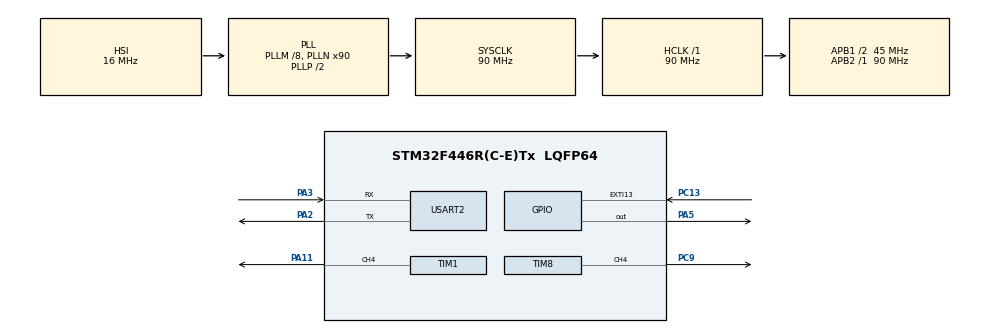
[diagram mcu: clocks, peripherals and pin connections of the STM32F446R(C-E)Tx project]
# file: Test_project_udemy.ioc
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Mcu.Family=STM32F4
Mcu.Name=STM32F446R(C-E)Tx
Mcu.Package=LQFP64
NVIC.PriorityGroup=NVIC_PRIORITYGROUP_4
NVIC.USART2_IRQn=true\:0\:0\:false\:false\:true\:true\:true
PA11.GPIO_ModeDefaultPP=GPIO_MODE_AF_PP
PA11.GPIO_PuPd=GPIO_NOPULL
PA11.GPIO_Speed=GPIO_SPEED_FREQ_LOW
PA11.Signal=S_TIM1_CH4
PA2.Mode=Asynchronous
PA2.Signal=USART2_TX
PA3.Mode=Asynchronous
PA3.Signal=USART2_RX
PA5.GPIO_ModeDefaultOutputPP=GPIO_MODE_OUTPUT_PP
PA5.GPIO_PuPd=GPIO_NOPULL
PA5.GPIO_Speed=GPIO_SPEED_FREQ_LOW
PA5.PinState=GPIO_PIN_RESET
PA5.Signal=GPIO_Output
PA8.Signal=S_TIM1_CH1
PC13.GPIO_ModeDefaultEXTI=GPIO_MODE_IT_RISING
PC13.GPIO_PuPd=GPIO_NOPULL
PC13.Signal=GPXTI13
PC9.GPIO_ModeDefaultPP=GPIO_MODE_AF_PP
PC9.GPIO_PuPd=GPIO_NOPULL
PC9.GPIO_Speed=GPIO_SPEED_FREQ_LOW
PC9.Signal=S_TIM8_CH4
PH0-OSC_IN.Mode=HSE-External-Oscillator
PH0-OSC_IN.Signal=RCC_OSC_IN
PH1-OSC_OUT.Mode=HSE-External-Oscillator
PH1-OSC_OUT.Signal=RCC_OSC_OUT
ProjectManager.HeapSize=0x200
ProjectManager.StackSize=0x400
ProjectManager.TargetToolchain=STM32CubeIDE
RCC.AHBFreq_Value=90000000
RCC.APB1CLKDivider=RCC_HCLK_DIV2
RCC.APB1Freq_Value=45000000
RCC.APB1TimFreq_Value=90000000
RCC.APB2Freq_Value=90000000
RCC.APB2TimFreq_Value=90000000
RCC.CortexFreq_Value=90000000
RCC.HCLKFreq_Value=90000000
RCC.PLLM=8
RCC.PLLN=90
RCC.SYSCLKFreq_VALUE=90000000
RCC.SYSCLKSource=RCC_SYSCLKSOURCE_PLLCLK
RCC.USBFreq_Value=90000000
RCC.VCOOutputFreq_Value=180000000
SH.S_TIM1_CH1.0=TIM1_CH1
SH.S_TIM1_CH4.0=TIM1_CH4,PWM Generation4 CH4
SH.S_TIM8_CH4.0=TIM8_CH4,PWM Generation4 CH4
TIM1.AutoReloadPreload=TIM_AUTORELOAD_PRELOAD_ENABLE
TIM1.Channel-PWM\ Generation4\ CH4=TIM_CHANNEL_4
TIM1.Period=180
TIM8.AutoReloadPreload=TIM_AUTORELOAD_PRELOAD_ENABLE
TIM8.Channel-PWM\ Generation4\ CH4=TIM_CHANNEL_4
TIM8.Period=257
USART2.VirtualMode=VM_ASYNC
VP_TIM1_VS_ClockSourceINT.Mode=Internal
VP_TIM8_VS_ClockSourceINT.Mode=Internal
board=custom

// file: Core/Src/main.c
/* USER CODE BEGIN Header */
/**
  ******************************************************************************
  * @file           : main.c
  * @brief          : Main program body
  ******************************************************************************
  * @attention
  *
  * <h2><center>&copy; Copyright (c) 2020 STMicroelectronics.
  * All rights reserved.</center></h2>
  *
  * This software component is licensed by ST under BSD 3-Clause license,
  * the "License"; You may not use this file except in compliance with the
  * License. You may obtain a copy of the License at:
  *                        opensource.org/licenses/BSD-3-Clause
  *
  ******************************************************************************
  */
/* USER CODE END Header */

#include "main.h"

/* USER CODE BEGIN Includes */
#include <string.h>
#include <stdio.h>
#include "Manager.h"
/* USER CODE END Includes */

TIM_HandleTypeDef htim1;
TIM_HandleTypeDef htim8;

UART_HandleTypeDef huart2;

/* USER CODE BEGIN PV */
extern char buf[10];
uint32_t *p; //pointer pointing to the address of registers

/* USER CODE END PV */

void SystemClock_Config(void);
static void MX_GPIO_Init(void);
static void MX_TIM1_Init(void);
static void MX_TIM8_Init(void);
static void MX_USART2_UART_Init(void);

int main(void)
{
  /* USER CODE BEGIN 1 */
//uint8_t msg1[] = "Hello World!\n\r";
  /* USER CODE END 1 */

  /* MCU Configuration--------------------------------------------------------*/

  /* Reset of all peripherals, Initializes the Flash interface and the Systick. */

	HAL_Init();

  /* USER CODE BEGIN Init */
  Manager_init();
  /* USER CODE END Init */

  /* Configure the system clock */
  SystemClock_Config();

  /* Initialize all configured peripherals */
  MX_GPIO_Init();
  MX_TIM1_Init();
  MX_TIM8_Init();
  MX_USART2_UART_Init();
  /* USER CODE BEGIN 2 */

  //HAL_TIM_PWM_Start(&htim1, TIM_CHANNEL_4);
  //HAL_TIM_PWM_Start(&htim8, TIM_CHANNEL_4);
  HAL_UART_Receive_IT(&huart2, buf, 1);
  /* USER CODE END 2 */

  /* Infinite loop */
  while (1)
  {

  }
}

void SystemClock_Config(void)
{
  RCC_OscInitTypeDef RCC_OscInitStruct = {0};
  RCC_ClkInitTypeDef RCC_ClkInitStruct = {0};

  /** Configure the main internal regulator output voltage
  */
  __HAL_RCC_PWR_CLK_ENABLE();
  __HAL_PWR_VOLTAGESCALING_CONFIG(PWR_REGULATOR_VOLTAGE_SCALE3);
  /** Initializes the CPU, AHB and APB busses clocks
  */
  RCC_OscInitStruct.OscillatorType = RCC_OSCILLATORTYPE_HSI;
  RCC_OscInitStruct.HSIState = RCC_HSI_ON;
  RCC_OscInitStruct.HSICalibrationValue = RCC_HSICALIBRATION_DEFAULT;
  RCC_OscInitStruct.PLL.PLLState = RCC_PLL_ON;
  RCC_OscInitStruct.PLL.PLLSource = RCC_PLLSOURCE_HSI;
  RCC_OscInitStruct.PLL.PLLM = 8;
  RCC_OscInitStruct.PLL.PLLN = 90;
  RCC_OscInitStruct.PLL.PLLP = RCC_PLLP_DIV2;
  RCC_OscInitStruct.PLL.PLLQ = 2;
  RCC_OscInitStruct.PLL.PLLR = 2;
  if (HAL_RCC_OscConfig(&RCC_OscInitStruct) != HAL_OK)
  {
    Error_Handler();
  }
  /** Initializes the CPU, AHB and APB busses clocks
  */
  RCC_ClkInitStruct.ClockType = RCC_CLOCKTYPE_HCLK|RCC_CLOCKTYPE_SYSCLK
                              |RCC_CLOCKTYPE_PCLK1|RCC_CLOCKTYPE_PCLK2;
  RCC_ClkInitStruct.SYSCLKSource = RCC_SYSCLKSOURCE_PLLCLK;
  RCC_ClkInitStruct.AHBCLKDivider = RCC_SYSCLK_DIV1;
  RCC_ClkInitStruct.APB1CLKDivider = RCC_HCLK_DIV2;
  RCC_ClkInitStruct.APB2CLKDivider = RCC_HCLK_DIV1;

  if (HAL_RCC_ClockConfig(&RCC_ClkInitStruct, FLASH_LATENCY_2) != HAL_OK)
  {
    Error_Handler();
  }
}

static void MX_TIM1_Init(void)
{

  TIM_ClockConfigTypeDef sClockSourceConfig = {0};
  TIM_MasterConfigTypeDef sMasterConfig = {0};
  TIM_OC_InitTypeDef sConfigOC = {0};
  TIM_BreakDeadTimeConfigTypeDef sBreakDeadTimeConfig = {0};

  htim1.Instance = TIM1;
  htim1.Init.Prescaler = 0;
  htim1.Init.CounterMode = TIM_COUNTERMODE_UP;
  htim1.Init.Period = 180;
  htim1.Init.ClockDivision = TIM_CLOCKDIVISION_DIV1;
  htim1.Init.RepetitionCounter = 0;
  htim1.Init.AutoReloadPreload = TIM_AUTORELOAD_PRELOAD_ENABLE;
  if (HAL_TIM_Base_Init(&htim1) != HAL_OK)
  {
    Error_Handler();
  }
  sClockSourceConfig.ClockSource = TIM_CLOCKSOURCE_INTERNAL;
  if (HAL_TIM_ConfigClockSource(&htim1, &sClockSourceConfig) != HAL_OK)
  {
    Error_Handler();
  }
  if (HAL_TIM_PWM_Init(&htim1) != HAL_OK)
  {
    Error_Handler();
  }
  sMasterConfig.MasterOutputTrigger = TIM_TRGO_RESET;
  sMasterConfig.MasterSlaveMode = TIM_MASTERSLAVEMODE_DISABLE;
  if (HAL_TIMEx_MasterConfigSynchronization(&htim1, &sMasterConfig) != HAL_OK)
  {
    Error_Handler();
  }
  sConfigOC.OCMode = TIM_OCMODE_PWM1;
  sConfigOC.Pulse = 90;
  sConfigOC.OCPolarity = TIM_OCPOLARITY_HIGH;
  sConfigOC.OCFastMode = TIM_OCFAST_DISABLE;
  sConfigOC.OCIdleState = TIM_OCIDLESTATE_RESET;
  sConfigOC.OCNIdleState = TIM_OCNIDLESTATE_RESET;
  if (HAL_TIM_PWM_ConfigChannel(&htim1, &sConfigOC, TIM_CHANNEL_4) != HAL_OK)
  {
    Error_Handler();
  }
  sBreakDeadTimeConfig.OffStateRunMode = TIM_OSSR_DISABLE;
  sBreakDeadTimeConfig.OffStateIDLEMode = TIM_OSSI_DISABLE;
  sBreakDeadTimeConfig.LockLevel = TIM_LOCKLEVEL_OFF;
  sBreakDeadTimeConfig.DeadTime = 0;
  sBreakDeadTimeConfig.BreakState = TIM_BREAK_DISABLE;
  sBreakDeadTimeConfig.BreakPolarity = TIM_BREAKPOLARITY_HIGH;
  sBreakDeadTimeConfig.AutomaticOutput = TIM_AUTOMATICOUTPUT_DISABLE;
  if (HAL_TIMEx_ConfigBreakDeadTime(&htim1, &sBreakDeadTimeConfig) != HAL_OK)
  {
    Error_Handler();
  }
  HAL_TIM_MspPostInit(&htim1);

}

static void MX_TIM8_Init(void)
{

  TIM_ClockConfigTypeDef sClockSourceConfig = {0};
  TIM_MasterConfigTypeDef sMasterConfig = {0};
  TIM_OC_InitTypeDef sConfigOC = {0};
  TIM_BreakDeadTimeConfigTypeDef sBreakDeadTimeConfig = {0};

  htim8.Instance = TIM8;
  htim8.Init.Prescaler = 0;
  htim8.Init.CounterMode = TIM_COUNTERMODE_UP;
  htim8.Init.Period = 257;
  htim8.Init.ClockDivision = TIM_CLOCKDIVISION_DIV1;
  htim8.Init.RepetitionCounter = 0;
  htim8.Init.AutoReloadPreload = TIM_AUTORELOAD_PRELOAD_ENABLE;
  if (HAL_TIM_Base_Init(&htim8) != HAL_OK)
  {
    Error_Handler();
  }
  sClockSourceConfig.ClockSource = TIM_CLOCKSOURCE_INTERNAL;
  if (HAL_TIM_ConfigClockSource(&htim8, &sClockSourceConfig) != HAL_OK)
  {
    Error_Handler();
  }
  if (HAL_TIM_PWM_Init(&htim8) != HAL_OK)
  {
    Error_Handler();
  }
  sMasterConfig.MasterOutputTrigger = TIM_TRGO_RESET;
  sMasterConfig.MasterSlaveMode = TIM_MASTERSLAVEMODE_DISABLE;
  if (HAL_TIMEx_MasterConfigSynchronization(&htim8, &sMasterConfig) != HAL_OK)
  {
    Error_Handler();
  }
  sConfigOC.OCMode = TIM_OCMODE_PWM1;
  sConfigOC.Pulse = 150;
  sConfigOC.OCPolarity = TIM_OCPOLARITY_HIGH;
  sConfigOC.OCFastMode = TIM_OCFAST_DISABLE;
  sConfigOC.OCIdleState = TIM_OCIDLESTATE_RESET;
  sConfigOC.OCNIdleState = TIM_OCNIDLESTATE_RESET;
  if (HAL_TIM_PWM_ConfigChannel(&htim8, &sConfigOC, TIM_CHANNEL_4) != HAL_OK)
  {
    Error_Handler();
  }
  sBreakDeadTimeConfig.OffStateRunMode = TIM_OSSR_DISABLE;
  sBreakDeadTimeConfig.OffStateIDLEMode = TIM_OSSI_DISABLE;
  sBreakDeadTimeConfig.LockLevel = TIM_LOCKLEVEL_OFF;
  sBreakDeadTimeConfig.DeadTime = 0;
  sBreakDeadTimeConfig.BreakState = TIM_BREAK_DISABLE;
  sBreakDeadTimeConfig.BreakPolarity = TIM_BREAKPOLARITY_HIGH;
  sBreakDeadTimeConfig.AutomaticOutput = TIM_AUTOMATICOUTPUT_DISABLE;
  if (HAL_TIMEx_ConfigBreakDeadTime(&htim8, &sBreakDeadTimeConfig) != HAL_OK)
  {
    Error_Handler();
  }
  HAL_TIM_MspPostInit(&htim8);

}

static void MX_USART2_UART_Init(void)
{

  huart2.Instance = USART2;
  huart2.Init.BaudRate = 115200;
  huart2.Init.WordLength = UART_WORDLENGTH_8B;
  huart2.Init.StopBits = UART_STOPBITS_1;
  huart2.Init.Parity = UART_PARITY_NONE;
  huart2.Init.Mode = UART_MODE_TX_RX;
  huart2.Init.HwFlowCtl = UART_HWCONTROL_NONE;
  huart2.Init.OverSampling = UART_OVERSAMPLING_16;
  if (HAL_UART_Init(&huart2) != HAL_OK)
  {
    Error_Handler();
  }

}

static void MX_GPIO_Init(void)
{
  GPIO_InitTypeDef GPIO_InitStruct = {0};

  /* GPIO Ports Clock Enable */
  __HAL_RCC_GPIOC_CLK_ENABLE();
  __HAL_RCC_GPIOH_CLK_ENABLE();
  __HAL_RCC_GPIOA_CLK_ENABLE();

  /*Configure GPIO pin Output Level */
  HAL_GPIO_WritePin(LED_GPIO_Port, LED_Pin, GPIO_PIN_RESET);

  /*Configure GPIO pin : PC13 */
  GPIO_InitStruct.Pin = GPIO_PIN_13;
  GPIO_InitStruct.Mode = GPIO_MODE_IT_RISING;
  GPIO_InitStruct.Pull = GPIO_NOPULL;
  HAL_GPIO_Init(GPIOC, &GPIO_InitStruct);

  /*Configure GPIO pin : LED_Pin */
  GPIO_InitStruct.Pin = LED_Pin;
  GPIO_InitStruct.Mode = GPIO_MODE_OUTPUT_PP;
  GPIO_InitStruct.Pull = GPIO_NOPULL;
  GPIO_InitStruct.Speed = GPIO_SPEED_FREQ_LOW;
  HAL_GPIO_Init(LED_GPIO_Port, &GPIO_InitStruct);

  /* EXTI interrupt init*/
  HAL_NVIC_SetPriority(EXTI15_10_IRQn, 0, 0);
  HAL_NVIC_EnableIRQ(EXTI15_10_IRQn);

}

/* USER CODE BEGIN 4 */

void USART1_IRQHandler(void)
{

}

/* USER CODE END 4 */

void Error_Handler(void)
{
}

/************************ (C) COPYRIGHT STMicroelectronics *****END OF FILE****/
